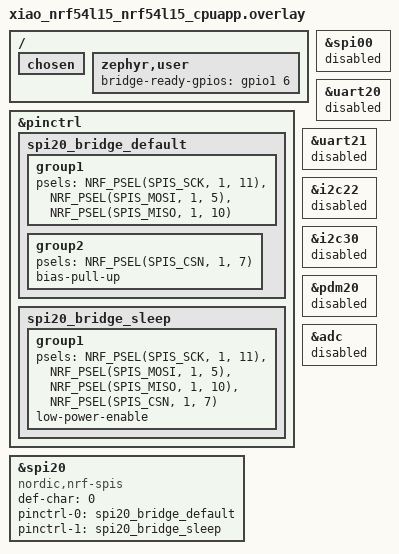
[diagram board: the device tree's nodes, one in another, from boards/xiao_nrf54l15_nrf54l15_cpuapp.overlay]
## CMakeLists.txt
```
# SPDX-License-Identifier: MIT OR Apache-2.0
cmake_minimum_required(VERSION 3.20.0)

find_package(Zephyr REQUIRED HINTS $ENV{ZEPHYR_BASE})
project(smol_wifi_receiver_nrf54l15)

target_sources(app PRIVATE
  src/main.c
  src/report_builder.c
  src/receiver_control.c
  src/receiver_storage.c
  src/rf_receiver.c
  src/spi_bridge.c
  src/test_generator.c
  ../../protocol/bridge_protocol.c
  ../../protocol/command_replay_cache.c
)

target_include_directories(app PRIVATE
  src
  ../../protocol
)
```

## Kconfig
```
# SPDX-License-Identifier: MIT OR Apache-2.0
mainmenu "Smol Wi-Fi receiver"

config SMOL_TEST_GENERATOR
	bool "Generate 16 synthetic trackers at 100 Hz each"
	default n
	help
	  Disables live RF after initialization and feeds deterministic RF-v2-style
	  records into the SPI report queue for soak and latency testing.

source "Kconfig.zephyr"
```

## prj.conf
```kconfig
# SPDX-License-Identifier: MIT OR Apache-2.0
CONFIG_ASSERT=y
CONFIG_RESET_ON_FATAL_ERROR=y
CONFIG_BOOT_BANNER=n

CONFIG_ESB=y
CONFIG_ESB_CLOCK_INIT=y
CONFIG_NRF_GRTC_START_SYSCOUNTER=y
CONFIG_CRC=y

CONFIG_GPIO=y
CONFIG_PINCTRL=y
CONFIG_SPI=y
CONFIG_SPI_ASYNC=y
CONFIG_SPI_SLAVE=y

CONFIG_FLASH=y
CONFIG_FLASH_MAP=y
CONFIG_FLASH_PAGE_LAYOUT=y
CONFIG_NVS=y
CONFIG_NVS_LOOKUP_CACHE=y

CONFIG_SERIAL=n
CONFIG_CONSOLE=n
CONFIG_UART_CONSOLE=n
CONFIG_USB_DEVICE_STACK=n

CONFIG_LOG=y
CONFIG_LOG_MODE_DEFERRED=y
CONFIG_USE_SEGGER_RTT=y
CONFIG_LOG_BACKEND_RTT=y
CONFIG_LOG_DEFAULT_LEVEL=3
CONFIG_LOG_BUFFER_SIZE=4096
CONFIG_LOG_PROCESS_THREAD_STACK_SIZE=2048

CONFIG_MAIN_STACK_SIZE=4096
CONFIG_ISR_STACK_SIZE=8192
CONFIG_SYSTEM_WORKQUEUE_STACK_SIZE=2048
CONFIG_HEAP_MEM_POOL_SIZE=2048
CONFIG_THREAD_NAME=y
```

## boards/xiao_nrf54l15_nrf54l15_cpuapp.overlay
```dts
/* SPDX-License-Identifier: MIT OR Apache-2.0 */
#include <zephyr/dt-bindings/pinctrl/nrf-pinctrl.h>

/ {
	chosen {
		/delete-property/ zephyr,console;
		/delete-property/ zephyr,shell-uart;
		/delete-property/ nordic,rpc-uart;
	};

	zephyr,user {
		bridge-ready-gpios = <&gpio1 6 GPIO_ACTIVE_HIGH>;
	};
};

&pinctrl {
	/*
	 * nRF54L15 peripheral signals cannot span GPIO ports. Keep SCK, MOSI,
	 * MISO, and CSN on P1; READY is the separate GPIO declared above.
	 */
	spi20_bridge_default: spi20_bridge_default {
		group1 {
			psels = <NRF_PSEL(SPIS_SCK, 1, 11)>,
				<NRF_PSEL(SPIS_MOSI, 1, 5)>,
				<NRF_PSEL(SPIS_MISO, 1, 10)>;
		};

		group2 {
			psels = <NRF_PSEL(SPIS_CSN, 1, 7)>;
			/* Keep the peripheral deselected while the ESP resets. */
			bias-pull-up;
		};
	};

	spi20_bridge_sleep: spi20_bridge_sleep {
		group1 {
			psels = <NRF_PSEL(SPIS_SCK, 1, 11)>,
				<NRF_PSEL(SPIS_MOSI, 1, 5)>,
				<NRF_PSEL(SPIS_MISO, 1, 10)>,
				<NRF_PSEL(SPIS_CSN, 1, 7)>;
			low-power-enable;
		};
	};
};

&spi00 { status = "disabled"; };

&spi20 {
	compatible = "nordic,nrf-spis";
	/delete-property/ rx-delay-supported;
	/delete-property/ rx-delay;
	status = "okay";
	def-char = <0>;
	pinctrl-0 = <&spi20_bridge_default>;
	pinctrl-1 = <&spi20_bridge_sleep>;
	pinctrl-names = "default", "sleep";
};

&uart20 { status = "disabled"; };
&uart21 { status = "disabled"; };
&i2c22 { status = "disabled"; };
&i2c30 { status = "disabled"; };
&pdm20 { status = "disabled"; };
&adc { status = "disabled"; };
```

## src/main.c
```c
/* SPDX-License-Identifier: MIT OR Apache-2.0 */
#include "report_builder.h"
#include "rf_receiver.h"
#include "spi_bridge.h"
#include "test_generator.h"

#include <zephyr/kernel.h>
#include <zephyr/logging/log.h>

LOG_MODULE_REGISTER(main, LOG_LEVEL_INF);

int main(void)
{
	report_builder_init();
	int result = rf_receiver_init();
	if (result != 0) {
		LOG_ERR("RF receiver initialization failed: %d", result);
		return result;
	}
	result = spi_bridge_init();
	if (result != 0) {
		LOG_ERR("SPI bridge initialization failed: %d", result);
		return result;
	}
	test_generator_init();
	LOG_INF("Smol Wi-Fi nRF54L15 receiver ready");
	return 0;
}
```

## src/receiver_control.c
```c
/* SPDX-License-Identifier: MIT OR Apache-2.0 */
#include "receiver_control.h"

#include "receiver_control_protocol.h"
#include "command_replay_cache.h"
#include "report_builder.h"
#include "rf_receiver.h"
#include "spi_bridge.h"

#include <errno.h>
#include <string.h>
#include <zephyr/kernel.h>
#include <zephyr/sys/reboot.h>

static struct sv_command_replay_cache cache;

static void reboot_work_handler(struct k_work *work)
{
	ARG_UNUSED(work);
	sys_reboot(SYS_REBOOT_COLD);
}

K_WORK_DELAYABLE_DEFINE(reboot_work, reboot_work_handler);

void receiver_control_init(void)
{
	sv_command_replay_init(&cache);
}

static uint8_t status_from_errno(int error)
{
	if (error == 0) return SV_STATUS_OK;
	if (error == -EINVAL) return SV_STATUS_BAD_REQUEST;
	if (error == -EPERM) return SV_STATUS_NOT_ALLOWED;
	if (error == -ENOENT) return SV_STATUS_NOT_FOUND;
	if (error == -EBUSY) return SV_STATUS_BUSY;
	return SV_STATUS_INTERNAL_ERROR;
}

static void basic_response(struct sv_bridge_message *response, uint8_t command, int result)
{
	response->payload[0] = command;
	response->payload[1] = status_from_errno(result);
	response->payload_length = 2;
	if (result != 0) {
		response->flags |= SV_BRIDGE_FLAG_ERROR;
	}
}

static void get_status(struct sv_bridge_message *response)
{
	struct rf_receiver_status rf_status;
	rf_receiver_get_status(&rf_status);
	struct sv_receiver_status_response status = {
		.command = SV_CMD_GET_STATUS,
		.status = SV_STATUS_OK,
		.protocol_version = SV_RECEIVER_CONTROL_VERSION,
		.flags = (rf_status.primary ? SV_RECEIVER_STATUS_PRIMARY : 0) |
			(rf_status.pairing ? SV_RECEIVER_STATUS_PAIRING : 0) |
			(rf_status.radio_enabled ? SV_RECEIVER_STATUS_RADIO_ENABLED : 0),
		.stored_trackers = rf_status.tracker_count,
		.uptime_ms = (uint32_t)k_uptime_get(),
		.rf_received = rf_status.received,
		.rf_crc_errors = rf_status.crc_errors,
		.report_queue_drops = report_builder_drops(),
		.spi_crc_errors = spi_bridge_crc_errors(),
	};
	memcpy(status.receiver_id, &rf_status.receiver_id, 6);
	memcpy(status.group_id, &rf_status.group_id, 6);
	memcpy(response->payload, &status, sizeof(status));
	response->payload_length = sizeof(status);
}

static void get_tracker_page(const struct sv_bridge_message *request,
	struct sv_bridge_message *response)
{
	uint8_t page = request->payload_length >= 2 ? request->payload[1] : 0;
	struct sv_receiver_tracker_page_response result = {
		.command = SV_CMD_GET_TRACKER_PAGE,
		.status = SV_STATUS_OK,
		.page = page,
	};
	struct rf_receiver_status status;
	rf_receiver_get_status(&status);
	uint8_t start = (uint8_t)(page * ARRAY_SIZE(result.entries));
	for (uint8_t id = start; id < status.tracker_count && result.count < ARRAY_SIZE(result.entries); ++id) {
		uint64_t address = rf_receiver_tracker(id);
		if (address == 0) continue;
		result.entries[result.count].id = id;
		memcpy(result.entries[result.count].address, &address, 6);
		result.count++;
	}
	memcpy(response->payload, &result, sizeof(result));
	response->payload_length = sizeof(result);
}

static void execute(const struct sv_bridge_message *request,
	struct sv_bridge_message *response)
{
	memset(response, 0, sizeof(*response));
	response->kind = SV_BRIDGE_COMMAND_RESPONSE;
	response->request_id = request->request_id;
	if (request->payload_length == 0) {
		basic_response(response, 0, -EINVAL);
		return;
	}

	uint8_t command = request->payload[0];
	switch (command) {
	case SV_CMD_GET_STATUS:
		get_status(response);
		break;
	case SV_CMD_GET_TRACKER_PAGE:
		get_tracker_page(request, response);
		break;
	case SV_CMD_SET_GROUP: {
		if (request->payload_length < sizeof(struct sv_receiver_set_group_request)) {
			basic_response(response, command, -EINVAL);
			break;
		}
		struct sv_receiver_set_group_request set_group;
		memcpy(&set_group, request->payload, sizeof(set_group));
		uint64_t group = 0;
		memcpy(&group, set_group.group_id, 6);
		basic_response(response, command,
			rf_receiver_set_group(set_group.secondary != 0, group));
		break;
	}
	case SV_CMD_START_PAIRING:
		basic_response(response, command, rf_receiver_start_pairing());
		break;
	case SV_CMD_STOP_PAIRING:
		basic_response(response, command, rf_receiver_stop_pairing());
		break;
	case SV_CMD_CLEAR_TRACKERS:
		basic_response(response, command, rf_receiver_clear_trackers());
		break;
	case SV_CMD_SET_RADIO_ENABLED:
		basic_response(response, command,
			request->payload_length >= 2 ? rf_receiver_set_enabled(request->payload[1] != 0) : -EINVAL);
		break;
	case SV_CMD_REBOOT:
		basic_response(response, command, 0);
		break;
	default:
		basic_response(response, command, -EINVAL);
		break;
	}
}

void receiver_control_handle(const struct sv_bridge_message *request,
	struct sv_bridge_message *response)
{
	if (sv_command_replay_find(&cache, request->request_id, response)) return;
	execute(request, response);
	sv_command_replay_store(&cache, request->request_id, response);

	if (request->payload_length > 0 &&
		(request->payload[0] == SV_CMD_REBOOT || request->payload[0] == SV_CMD_SET_GROUP) &&
		response->payload_length > 1 && response->payload[1] == SV_STATUS_OK) {
		/* Leave enough time for SPIS to return the response before rebooting. */
		(void)k_work_reschedule(&reboot_work, K_MSEC(100));
	}
}
```

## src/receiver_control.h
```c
/* SPDX-License-Identifier: MIT OR Apache-2.0 */
#ifndef SMOL_RECEIVER_CONTROL_H
#define SMOL_RECEIVER_CONTROL_H

#include "bridge_protocol.h"

void receiver_control_init(void);
void receiver_control_handle(const struct sv_bridge_message *request,
	struct sv_bridge_message *response);

#endif
```

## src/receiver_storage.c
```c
/* SPDX-License-Identifier: MIT OR Apache-2.0 */
#include "receiver_storage.h"

#include <errno.h>
#include <string.h>
#include <zephyr/fs/nvs.h>
#include <zephyr/drivers/flash.h>
#include <zephyr/storage/flash_map.h>
#include <zephyr/logging/log.h>

LOG_MODULE_REGISTER(receiver_storage, LOG_LEVEL_INF);

#define NVS_PARTITION storage_partition
#define STORAGE_ID_GROUP 1u
#define STORAGE_ID_TRACKER_COUNT 2u
#define STORAGE_ID_TRACKER_BASE 16u

static struct nvs_fs fs;
static uint64_t group_id;
static uint64_t trackers[SMOL_MAX_TRACKERS];
static uint8_t tracker_count;

static int read_or_zero(uint16_t id, void *data, size_t length)
{
	int result = nvs_read(&fs, id, data, length);
	if (result == -ENOENT) {
		memset(data, 0, length);
		return 0;
	}
	return result < 0 ? result : 0;
}

int receiver_storage_init(void)
{
	struct flash_pages_info info;
	fs.flash_device = FIXED_PARTITION_DEVICE(NVS_PARTITION);
	fs.offset = FIXED_PARTITION_OFFSET(NVS_PARTITION);
	if (!device_is_ready(fs.flash_device) ||
		flash_get_page_info_by_offs(fs.flash_device, fs.offset, &info) != 0) {
		return -ENODEV;
	}
	fs.sector_size = info.size;
	fs.sector_count = 4;
	int result = nvs_mount(&fs);
	if (result != 0) {
		LOG_ERR("NVS mount failed: %d", result);
		return result;
	}

	read_or_zero(STORAGE_ID_GROUP, &group_id, sizeof(group_id));
	read_or_zero(STORAGE_ID_TRACKER_COUNT, &tracker_count, sizeof(tracker_count));
	group_id &= 0xffffffffffffULL;
	if (tracker_count > SMOL_MAX_TRACKERS) {
		tracker_count = 0;
	}
	for (uint8_t id = 0; id < tracker_count; ++id) {
		read_or_zero((uint16_t)(STORAGE_ID_TRACKER_BASE + id), &trackers[id], sizeof(trackers[id]));
		trackers[id] &= 0xffffffffffffULL;
	}
	return 0;
}

uint64_t receiver_storage_group(void)
{
	return group_id;
}

int receiver_storage_set_group(uint64_t group)
{
	group_id = group & 0xffffffffffffULL;
	int result = nvs_write(&fs, STORAGE_ID_GROUP, &group_id, sizeof(group_id));
	return result < 0 ? result : 0;
}

uint8_t receiver_storage_tracker_count(void)
{
	return tracker_count;
}

uint64_t receiver_storage_tracker(uint8_t id)
{
	return id < tracker_count ? trackers[id] : 0;
}

int receiver_storage_set_tracker(uint8_t id, uint64_t address)
{
	if (id >= SMOL_MAX_TRACKERS) {
		return -EINVAL;
	}
	trackers[id] = address & 0xffffffffffffULL;
	int result = nvs_write(&fs, (uint16_t)(STORAGE_ID_TRACKER_BASE + id),
		&trackers[id], sizeof(trackers[id]));
	return result < 0 ? result : 0;
}

int receiver_storage_set_tracker_count(uint8_t count)
{
	if (count > SMOL_MAX_TRACKERS) {
		return -EINVAL;
	}
	tracker_count = count;
	int result = nvs_write(&fs, STORAGE_ID_TRACKER_COUNT, &tracker_count, sizeof(tracker_count));
	return result < 0 ? result : 0;
}

int receiver_storage_clear_trackers(void)
{
	for (uint8_t id = 0; id < tracker_count; ++id) {
		int result = nvs_delete(&fs, (uint16_t)(STORAGE_ID_TRACKER_BASE + id));
		if (result != 0 && result != -ENOENT) {
			return result;
		}
	}
	memset(trackers, 0, sizeof(trackers));
	return receiver_storage_set_tracker_count(0);
}
```

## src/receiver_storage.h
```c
/* SPDX-License-Identifier: MIT OR Apache-2.0 */
#ifndef SMOL_RECEIVER_STORAGE_H
#define SMOL_RECEIVER_STORAGE_H

#include <stdbool.h>
#include <stdint.h>

#include "report_builder.h"

int receiver_storage_init(void);
uint64_t receiver_storage_group(void);
int receiver_storage_set_group(uint64_t group);
uint8_t receiver_storage_tracker_count(void);
uint64_t receiver_storage_tracker(uint8_t id);
int receiver_storage_set_tracker(uint8_t id, uint64_t address);
int receiver_storage_set_tracker_count(uint8_t count);
int receiver_storage_clear_trackers(void);

#endif
```

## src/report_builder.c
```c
/* SPDX-License-Identifier: MIT OR Apache-2.0 */
#include "report_builder.h"

#include <string.h>
#include <zephyr/kernel.h>

#define REPORT_QUEUE_SIZE 128u
#define REGISTRATION_PERIOD_MS 100

static struct sv_smol_record queue[REPORT_QUEUE_SIZE];
static uint16_t read_index;
static uint16_t write_index;
static uint64_t tracker_addresses[SMOL_MAX_TRACKERS];
static uint8_t registration_cursor;
static int64_t last_registration_ms;
static uint32_t drops;
static struct k_spinlock lock;

static uint16_t advance(uint16_t index)
{
	return (uint16_t)((index + 1u) % REPORT_QUEUE_SIZE);
}

void report_builder_init(void)
{
	read_index = 0;
	write_index = 0;
	registration_cursor = 0;
	last_registration_ms = -REGISTRATION_PERIOD_MS;
	drops = 0;
}

void report_builder_set_tracker(uint8_t id, uint64_t address)
{
	if (id >= SMOL_MAX_TRACKERS) {
		return;
	}
	k_spinlock_key_t key = k_spin_lock(&lock);
	tracker_addresses[id] = address & 0xffffffffffffULL;
	k_spin_unlock(&lock, key);
}

void report_builder_clear_trackers(void)
{
	k_spinlock_key_t key = k_spin_lock(&lock);
	memset(tracker_addresses, 0, sizeof(tracker_addresses));
	read_index = write_index = 0;
	registration_cursor = 0;
	k_spin_unlock(&lock, key);
}

void report_builder_enqueue(const uint8_t data[SV_SMOL_RECORD_SIZE], uint8_t rssi,
	uint8_t sequence, uint8_t flags, bool replace_sensor_data)
{
	struct sv_smol_record record = {0};
	memcpy(record.data, data, sizeof(record.data));
	if (data[0] != 1u && data[0] != 4u) {
		record.data[15] = rssi;
	}
	record.metadata.sequence = sequence;
	record.metadata.rssi = rssi;
	record.metadata.flags = flags;

	k_spinlock_key_t key = k_spin_lock(&lock);
	if (replace_sensor_data) {
		for (uint16_t cursor = read_index; cursor != write_index; cursor = advance(cursor)) {
			if (queue[cursor].data[0] <= 223u && queue[cursor].data[1] == data[1]) {
				queue[cursor] = record;
				k_spin_unlock(&lock, key);
				return;
			}
		}
	}
	uint16_t next = advance(write_index);
	if (next == read_index) {
		drops++;
		k_spin_unlock(&lock, key);
		return;
	}
	queue[write_index] = record;
	write_index = next;
	k_spin_unlock(&lock, key);
}

static bool next_registration(uint8_t output[SV_SMOL_RECORD_SIZE])
{
	for (uint8_t offset = 0; offset < SMOL_MAX_TRACKERS; ++offset) {
		uint8_t id = (uint8_t)((registration_cursor + offset) % SMOL_MAX_TRACKERS);
		if (tracker_addresses[id] == 0) {
			continue;
		}
		memset(output, 0, SV_SMOL_RECORD_SIZE);
		output[0] = 255;
		output[1] = id;
		memcpy(&output[2], &tracker_addresses[id], 6);
		registration_cursor = (uint8_t)((id + 1u) % SMOL_MAX_TRACKERS);
		return true;
	}
	return false;
}

static bool has_registration(void)
{
	for (uint8_t id = 0; id < SMOL_MAX_TRACKERS; ++id) {
		if (tracker_addresses[id] != 0) {
			return true;
		}
	}
	return false;
}

bool report_builder_next(uint8_t output[SV_SMOL_REPORT_SIZE])
{
	struct sv_smol_record records[SV_SMOL_DATA_RECORDS] = {0};
	uint8_t queued = 0;
	const int64_t now = k_uptime_get();

	k_spinlock_key_t key = k_spin_lock(&lock);
	while (queued < SV_SMOL_DATA_RECORDS && read_index != write_index) {
		records[queued++] = queue[read_index];
		read_index = advance(read_index);
	}
	bool registration_due = has_registration() &&
		(now - last_registration_ms >= REGISTRATION_PERIOD_MS);
	if (queued == 0 && !registration_due) {
		k_spin_unlock(&lock, key);
		return false;
	}

	memset(output, 0, SV_SMOL_REPORT_SIZE);
	uint8_t valid_data = 0;
	for (uint8_t slot = 0; slot < queued; ++slot) {
		memcpy(&output[slot * SV_SMOL_RECORD_SIZE], records[slot].data, SV_SMOL_RECORD_SIZE);
		if (records[slot].data[0] <= 223u) {
			valid_data++;
		}
	}
	for (uint8_t slot = queued; slot < SV_SMOL_DATA_RECORDS; ++slot) {
		if (!next_registration(&output[slot * SV_SMOL_RECORD_SIZE])) {
			break;
		}
		registration_due = true;
	}
	if (registration_due) {
		last_registration_ms = now;
	}
	k_spin_unlock(&lock, key);

	uint8_t *metadata = &output[SV_SMOL_DATA_RECORDS * SV_SMOL_RECORD_SIZE];
	metadata[0] = SV_SMOL_METADATA_TYPE;
	metadata[1] = SV_SMOL_METADATA_MARKER;
	metadata[2] = SV_SMOL_METADATA_MAGIC;
	metadata[3] = SV_SMOL_METADATA_VERSION;
	metadata[4] = valid_data;
	for (uint8_t slot = 0; slot < queued; ++slot) {
		metadata[5 + slot * 3] = records[slot].metadata.sequence;
		metadata[6 + slot * 3] = records[slot].metadata.rssi;
		metadata[7 + slot * 3] = records[slot].metadata.flags;
	}
	metadata[15] = SV_SMOL_METADATA_END_MAGIC;
	return true;
}

bool report_builder_pending(void)
{
	k_spinlock_key_t key = k_spin_lock(&lock);
	bool pending = read_index != write_index ||
		(has_registration() &&
		 (k_uptime_get() - last_registration_ms >= REGISTRATION_PERIOD_MS));
	k_spin_unlock(&lock, key);
	return pending;
}

uint32_t report_builder_drops(void)
{
	return drops;
}
```

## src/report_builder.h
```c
/* SPDX-License-Identifier: MIT OR Apache-2.0 */
#ifndef SMOL_REPORT_BUILDER_H
#define SMOL_REPORT_BUILDER_H

#include <stdbool.h>
#include <stdint.h>

#include "smol_report.h"

#define SMOL_MAX_TRACKERS 32u

void report_builder_init(void);
void report_builder_set_tracker(uint8_t id, uint64_t address);
void report_builder_clear_trackers(void);
void report_builder_enqueue(const uint8_t data[SV_SMOL_RECORD_SIZE], uint8_t rssi,
	uint8_t sequence, uint8_t flags, bool replace_sensor_data);
bool report_builder_next(uint8_t output[SV_SMOL_REPORT_SIZE]);
bool report_builder_pending(void);
uint32_t report_builder_drops(void);

#endif
```

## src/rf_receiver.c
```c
/*
 * SlimeVR Code is placed under the MIT license.
 * Copyright (c) 2025 SlimeVR Contributors
 * SPDX-License-Identifier: MIT OR Apache-2.0
 */
#include "rf_receiver.h"

#include "receiver_storage.h"
#include "report_builder.h"

#include <errno.h>
#include <esb.h>
#include <hal/nrf_ficr.h>
#include <string.h>
#include <zephyr/drivers/clock_control/nrf_clock_control.h>
#include <zephyr/kernel.h>
#include <zephyr/logging/log.h>
#include <zephyr/sys/crc.h>

LOG_MODULE_REGISTER(rf_receiver, LOG_LEVEL_INF);

#define DEVICE_ADDRESS_MASK 0xffffffffffffULL
#define RF_V2_PACKET_SIZE 28u
#define RF_V2_VERSION 2u
#define RF_V2_CRC_SEED 0x93a409ebu

static const uint8_t discovery_base_addr_0[4] = {0x62, 0x39, 0x8a, 0xf2};
static const uint8_t discovery_prefixes[8] = {0xfe, 0xff, 0x29, 0x27, 0x09, 0x02, 0xb2, 0xd6};

static struct esb_payload rx_payload;
static struct esb_payload pair_reply = ESB_CREATE_PAYLOAD(0, 0, 0, 0, 0, 0, 0, 0, 0);
static uint64_t receiver_id;
static uint64_t group_id;
static uint64_t tracker_addresses[SMOL_MAX_TRACKERS];
static uint8_t tracker_count;
static bool primary;
static bool pairing;
static bool radio_enabled = true;
static bool esb_initialized;
static uint32_t received_packets;
static uint32_t crc_errors;
static uint32_t config_generation;
static struct k_mutex state_mutex;

struct pairing_persist_record {
	uint8_t id;
	uint8_t tracker_count;
	uint64_t address;
	uint32_t generation;
};

K_MSGQ_DEFINE(pairing_persist_queue, sizeof(struct pairing_persist_record), 8, 4);

static void persist_pairing_work_handler(struct k_work *work);
K_WORK_DEFINE(persist_pairing_work, persist_pairing_work_handler);

static uint64_t read_device_address(void)
{
	return (((uint64_t)NRF_FICR->DEVICEADDR[1] << 32) |
		NRF_FICR->DEVICEADDR[0]) & DEVICE_ADDRESS_MASK;
}

static int start_hf_clock(void)
{
	struct onoff_manager *manager = z_nrf_clock_control_get_onoff(CLOCK_CONTROL_NRF_SUBSYS_HF);
	struct onoff_client client;
	if (manager == NULL) {
		return -ENXIO;
	}
	sys_notify_init_spinwait(&client.notify);
	int result = onoff_request(manager, &client);
	if (result < 0) {
		return result;
	}
	int clock_result;
	while ((result = sys_notify_fetch_result(&client.notify, &clock_result)) == -EAGAIN) {
		k_yield();
	}
	return result == 0 ? clock_result : result;
}

static void derive_addresses(uint64_t group, uint8_t base1[4])
{
	uint8_t bytes[6];
	memcpy(bytes, &group, sizeof(bytes));
	for (uint8_t i = 0; i < 4; ++i) {
		base1[i] = (uint8_t)(bytes[i] + bytes[4]);
		if (base1[i] == 0x00 || base1[i] == 0x55 || base1[i] == 0xaa) {
			base1[i] = (uint8_t)(base1[i] + 8u);
		}
	}
}

static int add_tracker(uint8_t id, uint64_t address)
{
	address &= DEVICE_ADDRESS_MASK;
	if (id >= SMOL_MAX_TRACKERS || address == 0) {
		return -EINVAL;
	}
	if (tracker_addresses[id] != 0 && tracker_addresses[id] != address) {
		return -EADDRINUSE;
	}
	tracker_addresses[id] = address;
	if (id >= tracker_count) {
		tracker_count = (uint8_t)(id + 1u);
	}
	report_builder_set_tracker(id, address);
	return 0;
}

static void persist_pairing_work_handler(struct k_work *work)
{
	ARG_UNUSED(work);
	struct pairing_persist_record record;
	while (k_msgq_get(&pairing_persist_queue, &record, K_NO_WAIT) == 0) {
		k_mutex_lock(&state_mutex, K_FOREVER);
		int result = 0;
		if (record.generation == config_generation) {
			result = receiver_storage_set_tracker(record.id, record.address);
			if (result == 0) result = receiver_storage_set_tracker_count(record.tracker_count);
		}
		k_mutex_unlock(&state_mutex);
		if (result != 0) LOG_ERR("Unable to persist paired tracker %u: %d", record.id, result);
	}
}

static void handle_rf_v2(const struct esb_payload *payload)
{
	if (payload->data[23] != RF_V2_VERSION) {
		return;
	}
	uint32_t expected_crc;
	memcpy(&expected_crc, &payload->data[24], sizeof(expected_crc));
	uint32_t actual_crc = crc32_k_4_2_update(RF_V2_CRC_SEED, payload->data, 24);
	if (expected_crc != actual_crc) {
		crc_errors++;
		uint8_t diagnostic[SV_SMOL_RECORD_SIZE] = {251, 255};
		report_builder_enqueue(diagnostic, payload->rssi, payload->data[22],
			SV_SMOL_META_RF_V2, false);
		return;
	}

	uint8_t id = payload->data[1];
	uint64_t address = 0;
	memcpy(&address, &payload->data[16], 6);
	address &= DEVICE_ADDRESS_MASK;
	if (id >= SMOL_MAX_TRACKERS || payload->data[0] > 223u || address == 0) {
		return;
	}

	if (primary) {
		if (id >= tracker_count || tracker_addresses[id] != address) {
			return;
		}
	} else if (add_tracker(id, address) != 0) {
		return;
	}

	received_packets++;
	report_builder_enqueue(payload->data, payload->rssi, payload->data[22],
		SV_SMOL_META_SEQUENCE_VALID | SV_SMOL_META_RF_V2 | SV_SMOL_META_CRC_VALID,
		true);
}

static void handle_pair_request(const struct esb_payload *payload)
{
	if (!primary || !pairing || payload->length != 8 || payload->data[1] != 0) {
		return;
	}
	uint8_t checksum = crc8_ccitt(0x07, &payload->data[2], 6);
	if (checksum == 0) {
		checksum = 8;
	}
	if (checksum != payload->data[0]) {
		return;
	}
	uint64_t address = 0;
	memcpy(&address, &payload->data[2], 6);
	address &= DEVICE_ADDRESS_MASK;
	if (address == 0) {
		return;
	}

	uint8_t id = tracker_count;
	for (uint8_t cursor = 0; cursor < tracker_count; ++cursor) {
		if (tracker_addresses[cursor] == address) {
			id = cursor;
			break;
		}
	}
	if (id >= SMOL_MAX_TRACKERS || add_tracker(id, address) != 0) {
		return;
	}
	struct pairing_persist_record persist = {
		.id = id,
		.tracker_count = tracker_count,
		.address = address,
		.generation = config_generation,
	};
	if (k_msgq_put(&pairing_persist_queue, &persist, K_NO_WAIT) == 0) {
		(void)k_work_submit(&persist_pairing_work);
	} else {
		LOG_ERR("Pairing persistence queue full");
		return;
	}

	pair_reply.pipe = 0;
	pair_reply.noack = false;
	pair_reply.data[0] = checksum;
	pair_reply.data[1] = id;
	memcpy(&pair_reply.data[2], &receiver_id, 6);
	(void)esb_write_payload(&pair_reply);
	LOG_INF("Paired tracker %u: %012llx", id, address);
}

static void receiver_esb_event_handler(struct esb_evt const *event)
{
	if (event->evt_id != ESB_EVENT_RX_RECEIVED) {
		return;
	}
	while (esb_read_rx_payload(&rx_payload) == 0) {
		if (rx_payload.pipe == 0) {
			handle_pair_request(&rx_payload);
		} else if (rx_payload.length == RF_V2_PACKET_SIZE) {
			handle_rf_v2(&rx_payload);
		}
	}
}

static void stop_radio(void)
{
	if (esb_initialized) {
		(void)esb_stop_rx();
		(void)esb_disable();
		esb_initialized = false;
	}
}

static int start_radio(void)
{
	if (!radio_enabled || esb_initialized) {
		return 0;
	}
	uint8_t base1[4];
	derive_addresses(group_id, base1);
	struct esb_config config = ESB_DEFAULT_CONFIG;
	config.mode = ESB_MODE_PRX;
	config.event_handler = receiver_esb_event_handler;
	config.tx_output_power = 8;
	config.retransmit_count = 0;
	config.selective_auto_ack = true;
	int result = esb_init(&config);
	if (result == 0) result = esb_set_base_address_0(discovery_base_addr_0);
	if (result == 0) result = esb_set_base_address_1(base1);
	if (result == 0) result = esb_set_prefixes(discovery_prefixes, ARRAY_SIZE(discovery_prefixes));
	if (result == 0) result = esb_enable_pipes(pairing ? (BIT(0) | BIT(1)) : BIT(1));
	if (result == 0) result = esb_start_rx();
	if (result != 0) {
		(void)esb_disable();
		return result;
	}
	esb_initialized = true;
	return 0;
}

int rf_receiver_init(void)
{
	k_mutex_init(&state_mutex);
	receiver_id = read_device_address();
	int result = receiver_storage_init();
	if (result != 0) {
		return result;
	}
	group_id = receiver_storage_group();
	if (group_id == 0) {
		group_id = receiver_id;
	}
	primary = group_id == receiver_id;
	tracker_count = receiver_storage_tracker_count();
	for (uint8_t id = 0; id < tracker_count; ++id) {
		tracker_addresses[id] = receiver_storage_tracker(id);
		report_builder_set_tracker(id, tracker_addresses[id]);
	}
	pairing = primary && tracker_count == 0;
	result = start_hf_clock();
	if (result == 0) {
		result = start_radio();
	}
	LOG_INF("Receiver %012llx group %012llx (%s)", receiver_id, group_id,
		primary ? "primary" : "secondary");
	return result;
}

void rf_receiver_get_status(struct rf_receiver_status *status)
{
	k_mutex_lock(&state_mutex, K_FOREVER);
	unsigned int key = irq_lock();
	*status = (struct rf_receiver_status) {
		.receiver_id = receiver_id,
		.group_id = group_id,
		.primary = primary,
		.pairing = pairing,
		.radio_enabled = radio_enabled,
		.tracker_count = tracker_count,
		.received = received_packets,
		.crc_errors = crc_errors,
	};
	irq_unlock(key);
	k_mutex_unlock(&state_mutex);
}

uint64_t rf_receiver_tracker(uint8_t id)
{
	unsigned int key = irq_lock();
	uint64_t address = id < tracker_count ? tracker_addresses[id] : 0;
	irq_unlock(key);
	return address;
}

int rf_receiver_set_group(bool secondary, uint64_t requested_group)
{
	requested_group &= DEVICE_ADDRESS_MASK;
	if (secondary && requested_group == 0) {
		return -EINVAL;
	}
	k_mutex_lock(&state_mutex, K_FOREVER);
	stop_radio();
	config_generation++;
	uint64_t previous_group = group_id;
	bool previous_primary = primary;
	bool previous_pairing = pairing;
	group_id = secondary ? requested_group : receiver_id;
	primary = !secondary;
	pairing = false;
	int result = receiver_storage_set_group(secondary ? group_id : 0);
	int clear_result = receiver_storage_clear_trackers();
	if (result == 0) result = clear_result;
	if (result != 0) {
		group_id = previous_group;
		primary = previous_primary;
		pairing = previous_pairing;
		(void)receiver_storage_set_group(previous_primary ? 0 : previous_group);
		(void)start_radio();
		k_mutex_unlock(&state_mutex);
		return result;
	}
	k_msgq_purge(&pairing_persist_queue);
	memset(tracker_addresses, 0, sizeof(tracker_addresses));
	tracker_count = 0;
	report_builder_clear_trackers();
	k_mutex_unlock(&state_mutex);
	/* receiver_control schedules a reboot after the response reaches the ESP. */
	return 0;
}

int rf_receiver_start_pairing(void)
{
	k_mutex_lock(&state_mutex, K_FOREVER);
	if (!primary) {
		k_mutex_unlock(&state_mutex);
		return -EPERM;
	}
	stop_radio();
	pairing = true;
	int result = start_radio();
	k_mutex_unlock(&state_mutex);
	return result;
}

int rf_receiver_stop_pairing(void)
{
	k_mutex_lock(&state_mutex, K_FOREVER);
	stop_radio();
	pairing = false;
	int result = start_radio();
	k_mutex_unlock(&state_mutex);
	return result;
}

int rf_receiver_clear_trackers(void)
{
	k_mutex_lock(&state_mutex, K_FOREVER);
	stop_radio();
	config_generation++;
	int result = receiver_storage_clear_trackers();
	k_msgq_purge(&pairing_persist_queue);
	memset(tracker_addresses, 0, sizeof(tracker_addresses));
	tracker_count = 0;
	pairing = primary;
	report_builder_clear_trackers();
	int radio_result = start_radio();
	if (result == 0) result = radio_result;
	k_mutex_unlock(&state_mutex);
	return result;
}

int rf_receiver_set_enabled(bool enabled)
{
	k_mutex_lock(&state_mutex, K_FOREVER);
	stop_radio();
	radio_enabled = enabled;
	int result = start_radio();
	k_mutex_unlock(&state_mutex);
	return result;
}
```

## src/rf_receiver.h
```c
/* SPDX-License-Identifier: MIT OR Apache-2.0 */
#ifndef SMOL_RF_RECEIVER_H
#define SMOL_RF_RECEIVER_H

#include <stdbool.h>
#include <stdint.h>

struct rf_receiver_status {
	uint64_t receiver_id;
	uint64_t group_id;
	bool primary;
	bool pairing;
	bool radio_enabled;
	uint8_t tracker_count;
	uint32_t received;
	uint32_t crc_errors;
};

int rf_receiver_init(void);
void rf_receiver_get_status(struct rf_receiver_status *status);
uint64_t rf_receiver_tracker(uint8_t id);
int rf_receiver_set_group(bool secondary, uint64_t group_id);
int rf_receiver_start_pairing(void);
int rf_receiver_stop_pairing(void);
int rf_receiver_clear_trackers(void);
int rf_receiver_set_enabled(bool enabled);

#endif
```

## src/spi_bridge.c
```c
/* SPDX-License-Identifier: MIT OR Apache-2.0 */
#include "spi_bridge.h"

#include "bridge_protocol.h"
#include "receiver_control.h"
#include "report_builder.h"

#include <errno.h>
#include <string.h>
#include <zephyr/device.h>
#include <zephyr/drivers/gpio.h>
#include <zephyr/drivers/spi.h>
#include <zephyr/kernel.h>
#include <zephyr/logging/log.h>

LOG_MODULE_REGISTER(spi_bridge, LOG_LEVEL_INF);

#define SPI_NODE DT_NODELABEL(spi20)
#define USER_NODE DT_PATH(zephyr_user)
#define READY_LOW_GUARD_US 50u

static const struct device *spi_device = DEVICE_DT_GET(SPI_NODE);
static const struct gpio_dt_spec ready_gpio =
	GPIO_DT_SPEC_GET(USER_NODE, bridge_ready_gpios);
static const struct spi_config spi_config = {
	/* Maximum accepted peripheral clock; the jumper prototype controller uses 2 MHz. */
	.frequency = 8000000,
	.operation = SPI_OP_MODE_SLAVE | SPI_WORD_SET(8) | SPI_TRANSFER_MSB,
	.slave = 0,
};
static uint8_t tx_buffer[SV_BRIDGE_ENVELOPE_SIZE] __aligned(4);
static uint8_t rx_buffer[SV_BRIDGE_ENVELOPE_SIZE] __aligned(4);
K_SEM_DEFINE(transfer_done, 0, 1);
K_SEM_DEFINE(bridge_start, 0, 1);
static struct sv_bridge_message pending_response;
static bool response_pending;
static uint16_t tx_sequence;
static uint32_t crc_errors;

static void transfer_callback(const struct device *device, int result, void *user_data)
{
	ARG_UNUSED(device);
	ARG_UNUSED(result);
	ARG_UNUSED(user_data);
	(void)gpio_pin_set_dt(&ready_gpio, 0);
	k_sem_give(&transfer_done);
}

static void prepare_tx(void)
{
	struct sv_bridge_message message = {0};
	message.sequence = tx_sequence++;
	if (response_pending) {
		message = pending_response;
		message.sequence = (uint16_t)(tx_sequence - 1u);
		response_pending = false;
	} else if (report_builder_next(message.payload)) {
		message.kind = SV_BRIDGE_RECEIVER_REPORT;
		message.payload_length = SV_BRIDGE_PAYLOAD_SIZE;
	}
	if (report_builder_pending() || response_pending) {
		message.flags |= SV_BRIDGE_FLAG_MORE_PENDING;
	}
	sv_bridge_encode(tx_buffer, &message);
}

static void process_rx(void)
{
	struct sv_bridge_message request;
	if (!sv_bridge_decode(&request, rx_buffer)) {
		crc_errors++;
		return;
	}
	if (request.kind == SV_BRIDGE_COMMAND) {
		receiver_control_handle(&request, &pending_response);
		response_pending = true;
	}
}

static void spi_thread(void)
{
	struct spi_buf tx = {.buf = tx_buffer, .len = sizeof(tx_buffer)};
	struct spi_buf rx = {.buf = rx_buffer, .len = sizeof(rx_buffer)};
	struct spi_buf_set tx_set = {.buffers = &tx, .count = 1};
	struct spi_buf_set rx_set = {.buffers = &rx, .count = 1};

	k_sem_take(&bridge_start, K_FOREVER);
	while (true) {
		prepare_tx();
		memset(rx_buffer, 0, sizeof(rx_buffer));
		int result = spi_transceive_cb(spi_device, &spi_config, &tx_set, &rx_set,
			transfer_callback, NULL);
		if (result != 0) {
			LOG_ERR("Failed to arm SPIS: %d", result);
			k_msleep(10);
			continue;
		}
		(void)gpio_pin_set_dt(&ready_gpio, 1);
		k_sem_take(&transfer_done, K_FOREVER);
		process_rx();
		/* Let the controller observe READY low before this transfer is rearmed. */
		k_busy_wait(READY_LOW_GUARD_US);
	}
}

K_THREAD_DEFINE(spi_bridge_thread, 4096, spi_thread, NULL, NULL, NULL, 5, 0, 0);

int spi_bridge_init(void)
{
	if (!device_is_ready(spi_device) || !gpio_is_ready_dt(&ready_gpio)) {
		return -ENODEV;
	}
	int result = gpio_pin_configure_dt(&ready_gpio, GPIO_OUTPUT_INACTIVE);
	if (result == 0) {
		receiver_control_init();
		k_sem_give(&bridge_start);
	}
	return result;
}

uint32_t spi_bridge_crc_errors(void)
{
	return crc_errors;
}
```

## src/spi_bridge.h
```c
/* SPDX-License-Identifier: MIT OR Apache-2.0 */
#ifndef SMOL_SPI_BRIDGE_H
#define SMOL_SPI_BRIDGE_H

#include <stdint.h>

int spi_bridge_init(void);
uint32_t spi_bridge_crc_errors(void);

#endif
```

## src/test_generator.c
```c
/* SPDX-License-Identifier: MIT OR Apache-2.0 */
#include "test_generator.h"

#include "report_builder.h"
#include "rf_receiver.h"

#include <zephyr/kernel.h>

#if defined(CONFIG_SMOL_TEST_GENERATOR)

#define TEST_TRACKERS 16u
#define RECORD_INTERVAL_US (1000000u / (TEST_TRACKERS * 100u))

K_SEM_DEFINE(generator_start, 0, 1);

static void generator_thread(void)
{
	uint8_t sequences[TEST_TRACKERS] = {0};
	k_sem_take(&generator_start, K_FOREVER);
	uint8_t tracker = 0;
	while (true) {
		uint8_t record[SV_SMOL_RECORD_SIZE] = {0};
		record[0] = 1;
		record[1] = tracker;
		record[2] = sequences[tracker];
		record[3] = (uint8_t)k_uptime_get_32();
		report_builder_enqueue(record, 42, sequences[tracker]++,
			SV_SMOL_META_SEQUENCE_VALID | SV_SMOL_META_RF_V2 | SV_SMOL_META_CRC_VALID,
			true);
		tracker = (uint8_t)((tracker + 1u) % TEST_TRACKERS);
		k_usleep(RECORD_INTERVAL_US);
	}
}

K_THREAD_DEFINE(test_generator_thread, 2048, generator_thread, NULL, NULL, NULL, 6, 0, 0);

void test_generator_init(void)
{
	(void)rf_receiver_set_enabled(false);
	for (uint8_t id = 0; id < TEST_TRACKERS; ++id) {
		report_builder_set_tracker(id, 0x535600000000ULL + id + 1u);
	}
	k_sem_give(&generator_start);
}

#else

void test_generator_init(void) { }

#endif
```

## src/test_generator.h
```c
/* SPDX-License-Identifier: MIT OR Apache-2.0 */
#pragma once

void test_generator_init(void);
```
